# test_edge_cases register map
Vendor: Example Corp; Series: Test Series; File version: 1.0
Test MCU with various register sizes and edge cases
CPU: r0p1, little endian, no MPU, FPU, 4 interrupt priority bits
Registers are 32-bit, read-write, reset 0x0 unless marked. A register's access mark holds for its fields unless they carry their own. Offsets are from the block's base; lines under a group give offsets from that group; [hi:lo] are bit positions; {n}, {i} and the like mark numbered series; 'fields as' and 'values as' point back to an identical list; <NAME> marks a mode.

## Memory map
0x40010000 ? size 0x100 — Test peripheral with various register sizes

## ? — Test peripheral with various register sizes
Base 0x40010000
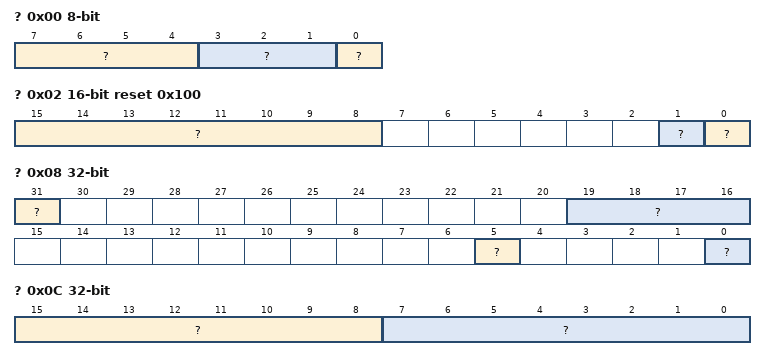
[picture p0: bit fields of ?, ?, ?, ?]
0x00 ? 8-bit — 8-bit Control Register
  [7:4] ? ro — Reserved
  [3:1] ? — Mode field
  [0] ? — Enable bit
0x02 ? 16-bit reset 0x100 — 16-bit Status Register
  [15:8] ? ro — Count value
  [1] ? ro — Error flag
  [0] ? ro — Ready flag
0x04 ? reset 0x12345678 — 32-bit Data Register
  [23:16] ? — Byte 2
  [15:8] ? — Byte 1
  [7:0] ? — Byte 0
  [?] ? — Most significant bit
0x08 ? — Register with sparse bit fields
  [31] ? — Bit 31
  [19:16] ? — Nibble at bits 16-19
  [5] ? — Bit 5
  [0] ? — Bit 0
0x0C ? — Register with special characters in name
  [15:8] ? — Field starting with numbers
  [7:0] ? — Field with special characters
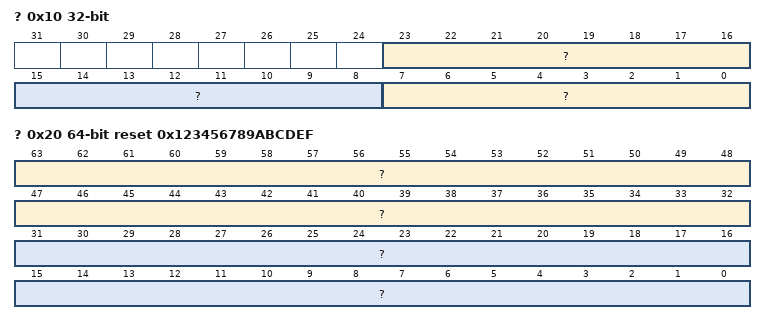
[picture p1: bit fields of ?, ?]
0x10 ? — Register with mixed access types
  [23:16] ? wo — Write-only field
  [15:8] ? ro — Read-only field
  [7:0] ? — Read-write field
0x20 ? 64-bit reset 0x123456789ABCDEF (reset mask 0xFFFFFFFF) — 64-bit Large Register
  [63:32] ? — Upper 32 bits
  [31:0] ? — Lower 32 bits
0x30 ? 128-bit (reset mask 0xFFFFFFFF) — 128-bit Huge Register
0x40 ?
  [15:0] ?
0x44 ? — Register with <HTML> & entities
  [7:0] ? — Field with "quotes" & symbols

## Licence text in the file
Commercial License
